# wsoc_con_dma_secure register map
Vendor: Texas Instruments
Peripheral module from a debugger description file (folder CC35X1).
Registers are 32-bit, access per field, reset 0x0 unless marked. A register's access mark holds for its fields unless they carry their own. Offsets are as the file gives them; lines under a group give offsets from that group; [hi:lo] are bit positions; {n}, {i} and the like mark numbered series; 'fields as' and 'values as' point back to an identical list; <NAME> marks a mode.

## wsoc_con_dma_secure
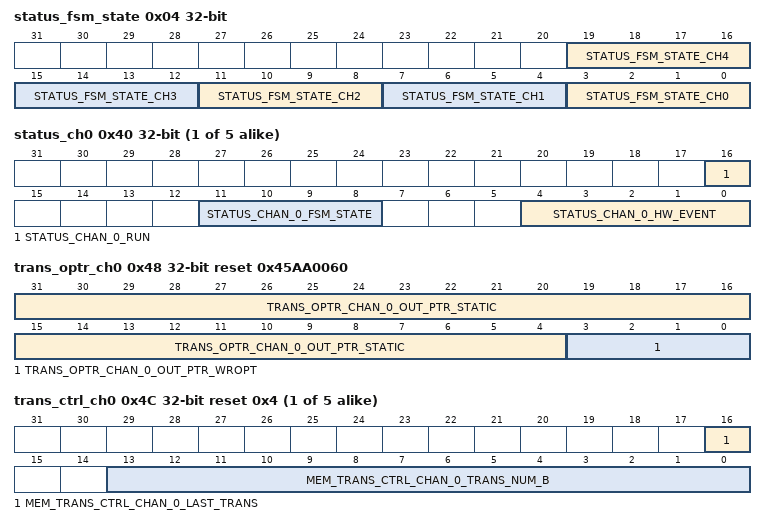
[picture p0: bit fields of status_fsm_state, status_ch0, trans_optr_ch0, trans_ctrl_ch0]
0x04 status_fsm_state ro — STATUS_FSM_STATE FSM States for all channels in one register: 0 - AES_IN 1 - AES_OUT 2 - UART_IN 3 - UART_OUT 4 - General Purpose
  [all] fields
    0=IDLE (Run command not recieved yet, Host is allowed to configure control registers, read status registers and execute a run command.); 1=PAUSE (Pause command recieved and irq raised. run command required to resume operation.); 2=EXCEPTION (Channel has encountered an error and requires assistance from host.); 3=DRAIN (ABORT or EXPECTION happend, draining FIFO.); 4=ABORT (SW abort signal, host must send Init command for channel to become active again.); 5=PRE_PAUSE (Copying remaining alignemnt buffer Bytes on write after pause command.); 7=LAST_2_PAUSE (Flushing write address aligner after pause command.); 8=PENDING_ARB (Channel is active, but arbiter has selected another channel for current transfer.); 9=COPY (Channel is active and is currently transferring data.); 10=COPY_LAST (Channel is active and is currently transfering the last block of data for current transaction.); 11=PAD (Channel is padding last block of Job.); 12=DONE (Transaction has completed, this state is active for one cycle. Next state is IDLE.); 13=SAVE_CTX (waiting for vbusp wready to transfer last word of block.); 14=WAIT_NXT_TRANS (Similar to IDLE, but explicitly states we are waiting for response from host.); 15=LAST_NO_PAD (The last transaction of last block of job when we do not do padding.)
  [4n+3:4n] STATUS_FSM_STATE_CH{n} (n=0..4) — Channel FSM State, see Enumeration for details
0x20 iidx ro — This register provides the highest priority enabled interrupt index. 0x00. means no event pending, 0x01 means interrupt pending for channel 0, 0x07 means interrupt pending for channel 6. Interrupt 1 is the highest priority, 2 next highest, 3,4, ...,7 is the least priority. That is, the least bit position that is set to 1 denotes the highest priority pending interrupt. channel 1 has highest priority, channel 6 has lowest. On each read, only one interrupt is indicated. On a read, the current interrupt (highest priority) is automatically cleared by the hardware and the corresponding interrupt flag in the RIS and MIS are cleared as well. After a read from the CPU (not from the debug interface), the register must be updated with the next highest priority interrupt, if none are pending, then it should display 0h
  [4:0] IIDX_STAT_RDCL — index of highest priority pending interrupt
    0=NO_INTR (No bit is set means there is no pending interrupt request); 1=IRQ_0 (Read and clear channel 0 irq); 2=IRQ_1 (Read and clear channel 1 irq); 4=IRQ_2 (Read and clear channel 2 irq); 3=IRQ_3 (Read and clear channel 3 irq); 5=IRQ_4 (Read and clear channel 4 irq); 6=IRQ_5 (Read and clear channel 5 irq); 7=IRQ_6 (Read and clear channel 6 irq)
0x24 imask — Interrupt mask. If a bit is set, then corresponding interrupt mask is set.
  [4:0] MEM_IMASK_IRQ rw — set 1 to enable irq
    0=DISABLED (Interrupt is masked out); 1=ENABLED (Interrupt will request an interrupt service routine and corresponding bit in [MIS] will be set)
0x28 ris ro — Raw interrupt status reflects all pending interrupts, regardless of masking. The RIS register allows the user to implement a poll scheme. A flag set in this register can be cleared by writing 1 to the ICLR register bit even if the corresponding IMASK bit is not enabled.
  [4:0] RIS_IRQ — bitmap of channel irqs
    1=SET (IRQ occured); 0=CLR (IRQ did not occur)
0x2C mis ro — Masked interrupt status. This is an AND of the IMASK and RIS registers.
  [4:0] MIS_IRQ — bitmap of channel irqs
    1=SET (IRQ occured); 0=CLR (IRQ did not occur)
0x30 iset — ISET allows interrupts to be set by software (useful in diagnostics and safety checks). Writing a 1 to a bit in ISET will set the event and therefore the related RIS bit also gets set. If the interrupt is enabled through the mask, then the corresponding MIS bit is also set.
  [4:0] ISET_IRQ_WRCL wo — set 1 to set channel
    0=NO_EFFECT (Writing 0 has no effect); 1=SET ([RIS] bit corresponding to IRQ_EXAMPLE0 is set)
0x34 iclr — Write a 1 to clear corresponding Interrupt.
  [4:0] ICLR_IRQ_WRCL wo — set 1 to clear irq
    0=NO_EFFECT (Writing 0 has no effect); 1=CLR ([RIS] clear bit corresponding to IRQ)
{0x40+0x20*i} status_ch{i} ro (i=0..4) — Channel Status FSM state and run indication.
  [16] STATUS_CHAN_{i}_RUN — Indication that channel is currently transfering data and is not idle. Channels that are waiting on arbitration are considered running.
    0=INACTIVE (Channel is IDLE or waiting for HOST); 1=ACTIVE (Channel is copying data or waiting on arbitration)
  [11:8] STATUS_CHAN_{i}_FSM_STATE — Channel FSM State, see Enumeration for details
    values as the fields of status_fsm_state
  [4:0] STATUS_CHAN_{i}_HW_EVENT — Channel status, bit mask. Multiple bits can be set at the same time
    0=NO_EVENT (No pending event); 1=JOB_DONE; 2=TRANS_DONE (Transaction done); 4=ABORTED (Transaction aborted by SW); 8=PAUSED (Transaction paused by SW); 16=EXC (An error has occured)
0x44 trans_iptr_ch0 rw — 32 bit address pointer of channel current input.
  [31:0] TRANS_IPTR_CHAN_0_IN_PTR_WROPT — address
0x48 trans_optr_ch0 reset 0x45AA0060 — 32 bit address pointer of channel current output.
  [31:4] TRANS_OPTR_CHAN_0_OUT_PTR_STATIC ro — address
  [3:0] TRANS_OPTR_CHAN_0_OUT_PTR_WROPT rw — address
{0x4C+0x20*i} trans_ctrl_ch{i} reset 0x4 (i=0..4) — Transaction control
  [16] MEM_TRANS_CTRL_CHAN_{i}_LAST_TRANS rw — Indicates this is the last DMA transaction on a specific crypto job, and therefore, the padding should apply to it. If this DMA transaction is not last, the channel must buffer the incomplete word and wait for the next DMA transaction command to be able to fetch the missing bytes. Once the last byte is reached, the DMA shall pad the remaining bytes. 0: not last transaction 1: last transaction
  [13:0] MEM_TRANS_CTRL_CHAN_{i}_TRANS_NUM_B rw — Number of bytes of the transaction to move from source to destination.
{0x50+0x20*i} trans_ctrl2_ch{i} (i=0..4) — DMA command interface
  [3:0] TRANS_CTRL2_CHAN_{i}_CMD_WRCL wo — command to resume, pause, stop or clear channel. STATUS_CHAN_X.RUN is a level signal that is high as long as the channel has not completed a tranfer.
    0=NOP (No effect); 1=RUN (Run - reactivate channel that is waiting on host. This is currently a pulse.); 2=PAUSE (Pause - stop reading data from source and change state to PAUSE once block has comleted.); 4=ABORT (Stop channel-operation immediately. Channel is in an invalid state until it is initialized again.); 8=INIT (Return Channel state to rest values. Requesred after an exception or Abort command were encountered to return channel to valid state.)
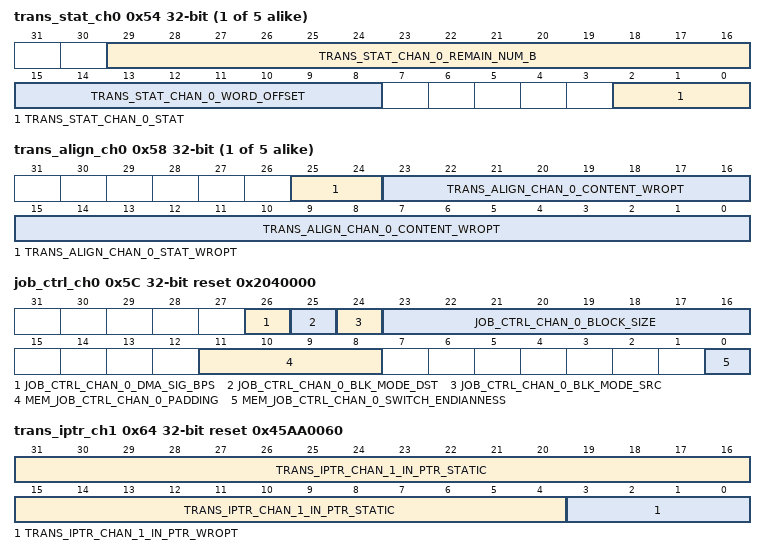
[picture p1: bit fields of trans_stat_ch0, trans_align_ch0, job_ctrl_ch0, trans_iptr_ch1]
{0x54+0x20*i} trans_stat_ch{i} ro (i=0..4) — Job completion reason - either last transaction or exception
  [29:16] TRANS_STAT_CHAN_{i}_REMAIN_NUM_B — Number of bytes remaining to complete the transaction. Loads (MEM_TRANS_NUM_B - TRANS_ALIGN.STAT_WROPT) and decrements the value for each transfer. This value should be read before context switch and written back to MEM_TRANS_NUM_B. The value of TRANS_ALIGN must be updated as well read and written back as well. The number of autstanding bytes should be equal to TRANS_STAT_CHAN_{i}_REMAIN_NUM_B+TRANS_ALIGN.CONTENT_WROPT
  [15:8] TRANS_STAT_CHAN_{i}_WORD_OFFSET — Offset in words from block boundary. Represents the number of words to be read from accelerator before context switch.
  [2:0] TRANS_STAT_CHAN_{i}_STAT — channel vbusp rstatus recieved at one of the master ports. Once an error is encountered the channel will enter an Exception state and stay the until an init command is recieved. ICLR does not affect this status.
    0=NO_ERR (No vbusp read error); 1=ADDR_ERR (Address error 1. No slave has this address 2. reserved address 3. wrong access type(read/write)); 2=PROTECTION_ERR (Improper priv/privid); 3=TIMEOUT_ERR (watchdog timeout - unsupported); 4=DATA_ERR (Data integrity error unsupported); 5=ADDR_MODE_ERR (vbus amode not supported); 7=EXCLUSIVE_RD_ERR (Exclusive read is not supported.); 6=MPPC_ERR (MPPC Fault occured)
{0x58+0x20*i} trans_align_ch{i} (i=0..4) — content and number of bytes in alignment buffer
  [25:24] TRANS_ALIGN_CHAN_{i}_STAT_WROPT rw — Number of bytes in the alignment buffer. In case of context switch, this field need to be read before context is swapped out and re written after the context is swapped back in.
    0=LEN_0 (No words in buffer); 1=LEN_1 (One word in buffer); 2=LEN_2 (Two words in buffer); 3=LEN_3 (Three words in buffer)
  [23:0] TRANS_ALIGN_CHAN_{i}_CONTENT_WROPT rw — 3 bytes of channel alignment FIFO. offset: 0x0: oldest data- lowest address 0x1: Data 0x2: Newest Data - highest address 0x3: Reserved
0x5C job_ctrl_ch0 reset 0x2040000 — Job control register
  [26] JOB_CTRL_CHAN_0_DMA_SIG_BPS ro — tie high channel DMA req signal. This is useful to change a channel dedicated to a specific crypto engine to a general usage channel.
    0=CLR (No channel is bypassed); 1=SET (channel bypass)
  [25] JOB_CTRL_CHAN_0_BLK_MODE_DST ro — Destination pointer wrap around mode 0: no wrap around(non block mode) 1: with wrap around(block mode)
  [24] JOB_CTRL_CHAN_0_BLK_MODE_SRC ro — source pointer wrap around mode 0: no wrap around(non block mode) 1: with wrap around(block mode)
  [23:16] JOB_CTRL_CHAN_0_BLOCK_SIZE ro — size of the block in words. If block mode is enabled, defines the address wrap around. Since channel arbitration decisions are made every block, this also effect how much bandwidth is given to a specific channel. AES - 4 UART - 1
  [11:8] MEM_JOB_CTRL_CHAN_0_PADDING rw — destination padding pattern. This field has only an effect if block_mode_dest is asserted. If the number of bytes provided is not sufficient to complete 1 block, the DMA engine shall pad the remaining bytes to provide 1 full block of data to the accelerator. Some of the accelerators already support a subset of padding schemes, hence a partial last block is not necessarily an error. Note that FIPS andf RFC are in big endian. See crypto engine documentation for details. 0: No Padding. If the DMA is unable to transfer a full word (and also finish a block), it must keep up to 3 bytes that were already read in a buffer. Once the next pointer (gather function) is programed (automatically or by the software), it resumes filling up words to complete a block. The buffer is cleared (might be a simple pointer re-init) by setting the init field to 1. 1: (Poly1305, AES-CCM) all zeros. 2: (AES-CMAC) 0x80 followed by all zeros. 3: (SHAKE) pad10*1. Depending on the rate (r=1600-c), the DMA forms an integer multiple of r. Message || 0x1F || 00...0 || 0x80. The DMA adds a 0x1F (for SHAKE) after the last byte of the message, then all 0s, then 0x80 at the last byte. 4: Pad with 0x01, 0x02, 0x03,...,0xn (where n is the number of padding bytes) (TBD as this one might very complex to implement along with the byte realignment requirement) 5: All zeros except for the last byte which says how many bytes of padding there are (ANSI X.923). E.g. 0x00 0x00 0x00 0x04 6: Pad with repeated byte stating how many padding bytes there are (PKCS#7 https://tools.ietf.org/html/rfc5652#section-6.3). E.g. 0x03 0x03 0x03 7: Pad with padding length. TLS padding: https://www.ietf.org/rfc/rfc5246.txt. Message + mac + padding length + padding length repeated. E.g. xx 0x03 0x03 0x03 0x03. (see section 6.2.3.2. of the link above for a full explanation). Note: SHA-1, 224, 256 & MD5 https://www.ietf.org/rfc/rfc1321.txt (3.1) http://nvlpubs.nist.gov/nistpubs/FIPS/NIST.FIPS.180-4.pdf (5.1.1) -Append 1 bit, then zero out to the 448th/512th bits. (The length of the message goes in 449-512). SHA-384, 512 http://nvlpubs.nist.gov/nistpubs/FIPS/NIST.FIPS.180-4.pdf (5.1.2) -Append 1 bit, zero out to the 896th/1024th bit.
    0=NO_PADDING (No Padding. If the DMA is unable to transfer a full word (and also finish a block), it must keep up to 3 bytes that were already read in a buffer. Once the next pointer (gather function) is programed (automatically or by the software), it resumes filling up words to complete a block. The buffer is cleared (might be a simple pointer re-init) by setting the init field to 1.); 1=ALL_ZEROS ((Poly1305, AES-CCM) all zeros.); 3=SHAKE ((SHAKE) pad10*1. Depending on the rate (r=1600-c), the DMA forms an integer multiple of r. Message || 0x1F || 00...0 || 0x80. The DMA adds a 0x1F (for SHAKE) after the last byte of the message, then all 0s, then 0x80 at the last byte.); 4=INCREMENT (Pad with 0x01, 0x02, 0x03,...,0xn (where n is the number of padding bytes) (TBD as this one might very complex to implement along with the byte realignment requirement)); 5=ANSIX923 (All zeros except for the last byte which says how many bytes of padding there are (ANSI X.923). E.g. 0x00 0x00 0x00 0x04); 6=PKCS7 (Pad with repeated byte stating how many padding bytes there are (PKCS#7 https://tools.ietf.org/html/rfc5652#section-6.3). E.g. 0x03 0x03 0x03); 7=TLS (Pad with padding length. TLS padding: https://www.ietf.org/rfc/rfc5246.txt. Message + mac + padding length + padding length repeated. E.g. xx 0x03 0x03 0x03 0x03. (see section 6.2.3.2. of the link above for a full explanation).)
  [0] MEM_JOB_CTRL_CHAN_0_SWITCH_ENDIANNESS rw — source pointer wrap around mode 0: no wrap around(non block mode) 1: with wrap around(block mode)
    0=NO_ENDIANNESS_SWITCH; 1=SWITCH_ENDIANNESS
0x64 trans_iptr_ch1 reset 0x45AA0060 — 32 bit address pointer of channel current input.
  [31:4] TRANS_IPTR_CHAN_1_IN_PTR_STATIC ro — address
  [3:0] TRANS_IPTR_CHAN_1_IN_PTR_WROPT rw — address
0x68 trans_optr_ch1 rw — 32 bit address pointer of channel current output.
  [31:0] TRANS_OPTR_CHAN_1_OUT_PTR_WROPT — address
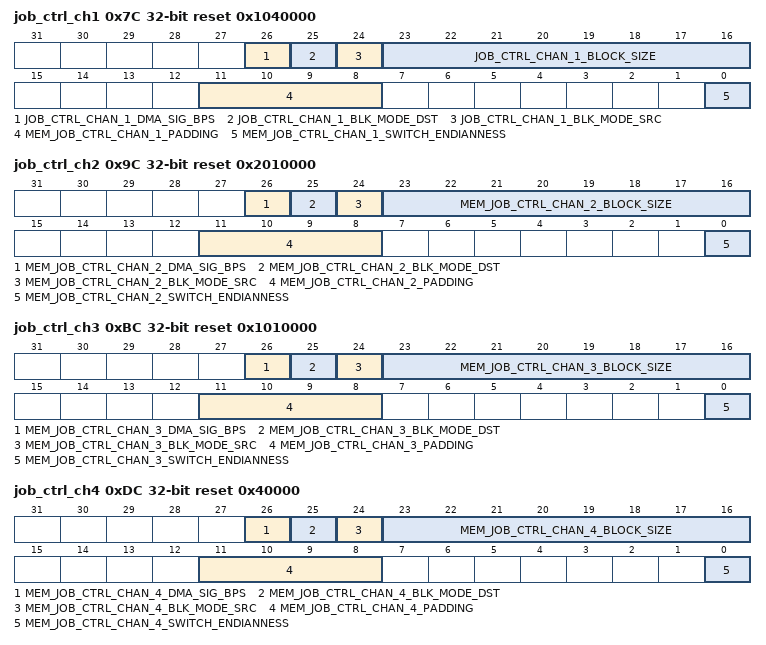
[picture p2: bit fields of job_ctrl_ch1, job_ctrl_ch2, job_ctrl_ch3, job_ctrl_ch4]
0x7C job_ctrl_ch1 reset 0x1040000 — Job control register
  [26] JOB_CTRL_CHAN_1_DMA_SIG_BPS ro — tie high channel DMA req signal. This is useful to change a channel dedicated to a specific crypto engine to a general usage channel.
    0=CLR (No channel is bypassed); 1=SET (channel bypass)
  [25] JOB_CTRL_CHAN_1_BLK_MODE_DST ro — Destination pointer wrap around mode 0: no wrap around(non block mode) 1: with wrap around(block mode)
  [24] JOB_CTRL_CHAN_1_BLK_MODE_SRC ro — source pointer wrap around mode 0: no wrap around(non block mode) 1: with wrap around(block mode)
  [23:16] JOB_CTRL_CHAN_1_BLOCK_SIZE ro — size of the block in words. If block mode is enabled, defines the address wrap around. Since channel arbitration decisions are made every block, this also effect how much bandwidth is given to a specific channel. AES - 4 UART - 1
  [11:8] MEM_JOB_CTRL_CHAN_1_PADDING rw — destination padding pattern. This field has only an effect if block_mode_dest is asserted. If the number of bytes provided is not sufficient to complete 1 block, the DMA engine shall pad the remaining bytes to provide 1 full block of data to the accelerator. Some of the accelerators already support a subset of padding schemes, hence a partial last block is not necessarily an error. Note that FIPS andf RFC are in big endian. See crypto engine documentation for details. 0: No Padding. If the DMA is unable to transfer a full word (and also finish a block), it must keep up to 3 bytes that were already read in a buffer. Once the next pointer (gather function) is programed (automatically or by the software), it resumes filling up words to complete a block. The buffer is cleared (might be a simple pointer re-init) by setting the init field to 1. 1: (Poly1305, AES-CCM) all zeros. 2: (AES-CMAC) 0x80 followed by all zeros. 3: (SHAKE) pad10*1. Depending on the rate (r=1600-c), the DMA forms an integer multiple of r. Message || 0x1F || 00...0 || 0x80. The DMA adds a 0x1F (for SHAKE) after the last byte of the message, then all 0s, then 0x80 at the last byte. 4: Pad with 0x01, 0x02, 0x03,...,0xn (where n is the number of padding bytes) (TBD as this one might very complex to implement along with the byte realignment requirement) 5: All zeros except for the last byte which says how many bytes of padding there are (ANSI X.923). E.g. 0x00 0x00 0x00 0x04 6: Pad with repeated byte stating how many padding bytes there are (PKCS#7 https://tools.ietf.org/html/rfc5652#section-6.3). E.g. 0x03 0x03 0x03 7: Pad with padding length. TLS padding: https://www.ietf.org/rfc/rfc5246.txt. Message + mac + padding length + padding length repeated. E.g. xx 0x03 0x03 0x03 0x03. (see section 6.2.3.2. of the link above for a full explanation). Note: SHA-1, 224, 256 & MD5 https://www.ietf.org/rfc/rfc1321.txt (3.1) http://nvlpubs.nist.gov/nistpubs/FIPS/NIST.FIPS.180-4.pdf (5.1.1) -Append 1 bit, then zero out to the 448th/512th bits. (The length of the message goes in 449-512). SHA-384, 512 http://nvlpubs.nist.gov/nistpubs/FIPS/NIST.FIPS.180-4.pdf (5.1.2) -Append 1 bit, zero out to the 896th/1024th bit.
    values as job_ctrl_ch0.MEM_JOB_CTRL_CHAN_0_PADDING
  [0] MEM_JOB_CTRL_CHAN_1_SWITCH_ENDIANNESS rw — source pointer wrap around mode 0: no wrap around(non block mode) 1: with wrap around(block mode)
    0=NO_ENDIANNESS_SWITCH; 1=SWITCH_ENDIANNESS
0x84 trans_iptr_ch2 rw — 32 bit address pointer of channel current input.
  [31:0] TRANS_IPTR_CHAN_2_IN_PTR_WROPT — address
0x88 trans_optr_ch2 rw reset 0x45860000 — 32 bit address pointer of channel current output.
  [31:0] TRANS_OPTR_CHAN_2_OUT_PTR_WROPT — address
0x9C job_ctrl_ch2 reset 0x2010000 — Job control register
  [26] MEM_JOB_CTRL_CHAN_2_DMA_SIG_BPS rw — tie high channel DMA req signal. This is useful to change a channel dedicated to a specific crypto engine to a general usage channel.
    0=CLR (No channel is bypassed); 1=SET (channel bypass)
  [25] MEM_JOB_CTRL_CHAN_2_BLK_MODE_DST rw — Destination pointer wrap around mode 0: no wrap around(non block mode) 1: with wrap around(block mode)
  [24] MEM_JOB_CTRL_CHAN_2_BLK_MODE_SRC rw — source pointer wrap around mode 0: no wrap around(non block mode) 1: with wrap around(block mode)
  [23:16] MEM_JOB_CTRL_CHAN_2_BLOCK_SIZE rw — size of the block in words. If block mode is enabled, defines the address wrap around. Since channel arbitration decisions are made every block, this also effect how much bandwidth is given to a specific channel. AES - 4 UART - 1
  [11:8] MEM_JOB_CTRL_CHAN_2_PADDING rw — destination padding pattern. This field has only an effect if block_mode_dest is asserted. If the number of bytes provided is not sufficient to complete 1 block, the DMA engine shall pad the remaining bytes to provide 1 full block of data to the accelerator. Some of the accelerators already support a subset of padding schemes, hence a partial last block is not necessarily an error. Note that FIPS andf RFC are in big endian. See crypto engine documentation for details. 0: No Padding. If the DMA is unable to transfer a full word (and also finish a block), it must keep up to 3 bytes that were already read in a buffer. Once the next pointer (gather function) is programed (automatically or by the software), it resumes filling up words to complete a block. The buffer is cleared (might be a simple pointer re-init) by setting the init field to 1. 1: (Poly1305, AES-CCM) all zeros. 2: (AES-CMAC) 0x80 followed by all zeros. 3: (SHAKE) pad10*1. Depending on the rate (r=1600-c), the DMA forms an integer multiple of r. Message || 0x1F || 00...0 || 0x80. The DMA adds a 0x1F (for SHAKE) after the last byte of the message, then all 0s, then 0x80 at the last byte. 4: Pad with 0x01, 0x02, 0x03,...,0xn (where n is the number of padding bytes) (TBD as this one might very complex to implement along with the byte realignment requirement) 5: All zeros except for the last byte which says how many bytes of padding there are (ANSI X.923). E.g. 0x00 0x00 0x00 0x04 6: Pad with repeated byte stating how many padding bytes there are (PKCS#7 https://tools.ietf.org/html/rfc5652#section-6.3). E.g. 0x03 0x03 0x03 7: Pad with padding length. TLS padding: https://www.ietf.org/rfc/rfc5246.txt. Message + mac + padding length + padding length repeated. E.g. xx 0x03 0x03 0x03 0x03. (see section 6.2.3.2. of the link above for a full explanation). Note: SHA-1, 224, 256 & MD5 https://www.ietf.org/rfc/rfc1321.txt (3.1) http://nvlpubs.nist.gov/nistpubs/FIPS/NIST.FIPS.180-4.pdf (5.1.1) -Append 1 bit, then zero out to the 448th/512th bits. (The length of the message goes in 449-512). SHA-384, 512 http://nvlpubs.nist.gov/nistpubs/FIPS/NIST.FIPS.180-4.pdf (5.1.2) -Append 1 bit, zero out to the 896th/1024th bit.
    values as job_ctrl_ch0.MEM_JOB_CTRL_CHAN_0_PADDING
  [0] MEM_JOB_CTRL_CHAN_2_SWITCH_ENDIANNESS rw — source pointer wrap around mode 0: no wrap around(non block mode) 1: with wrap around(block mode)
    0=NO_ENDIANNESS_SWITCH; 1=SWITCH_ENDIANNESS
0xA4 trans_iptr_ch3 rw reset 0x45860000 — 32 bit address pointer of channel current input.
  [31:0] TRANS_IPTR_CHAN_3_IN_PTR_WROPT — address
0xA8 trans_optr_ch3 rw — 32 bit address pointer of channel current output.
  [31:0] TRANS_OPTR_CHAN_3_OUT_PTR_WROPT — address
0xBC job_ctrl_ch3 reset 0x1010000 — Job control register
  [26] MEM_JOB_CTRL_CHAN_3_DMA_SIG_BPS rw — tie high channel DMA req signal. This is useful to change a channel dedicated to a specific crypto engine to a general usage channel.
    0=CLR (No channel is bypassed); 1=SET (channel bypass)
  [25] MEM_JOB_CTRL_CHAN_3_BLK_MODE_DST rw — Destination pointer wrap around mode 0: no wrap around(non block mode) 1: with wrap around(block mode)
  [24] MEM_JOB_CTRL_CHAN_3_BLK_MODE_SRC rw — source pointer wrap around mode 0: no wrap around(non block mode) 1: with wrap around(block mode)
  [23:16] MEM_JOB_CTRL_CHAN_3_BLOCK_SIZE rw — size of the block in words. If block mode is enabled, defines the address wrap around. Since channel arbitration decisions are made every block, this also effect how much bandwidth is given to a specific channel. AES - 4 UART - 1
  [11:8] MEM_JOB_CTRL_CHAN_3_PADDING rw — destination padding pattern. This field has only an effect if block_mode_dest is asserted. If the number of bytes provided is not sufficient to complete 1 block, the DMA engine shall pad the remaining bytes to provide 1 full block of data to the accelerator. Some of the accelerators already support a subset of padding schemes, hence a partial last block is not necessarily an error. Note that FIPS andf RFC are in big endian. See crypto engine documentation for details. 0: No Padding. If the DMA is unable to transfer a full word (and also finish a block), it must keep up to 3 bytes that were already read in a buffer. Once the next pointer (gather function) is programed (automatically or by the software), it resumes filling up words to complete a block. The buffer is cleared (might be a simple pointer re-init) by setting the init field to 1. 1: (Poly1305, AES-CCM) all zeros. 2: (AES-CMAC) 0x80 followed by all zeros. 3: (SHAKE) pad10*1. Depending on the rate (r=1600-c), the DMA forms an integer multiple of r. Message || 0x1F || 00...0 || 0x80. The DMA adds a 0x1F (for SHAKE) after the last byte of the message, then all 0s, then 0x80 at the last byte. 4: Pad with 0x01, 0x02, 0x03,...,0xn (where n is the number of padding bytes) (TBD as this one might very complex to implement along with the byte realignment requirement) 5: All zeros except for the last byte which says how many bytes of padding there are (ANSI X.923). E.g. 0x00 0x00 0x00 0x04 6: Pad with repeated byte stating how many padding bytes there are (PKCS#7 https://tools.ietf.org/html/rfc5652#section-6.3). E.g. 0x03 0x03 0x03 7: Pad with padding length. TLS padding: https://www.ietf.org/rfc/rfc5246.txt. Message + mac + padding length + padding length repeated. E.g. xx 0x03 0x03 0x03 0x03. (see section 6.2.3.2. of the link above for a full explanation). Note: SHA-1, 224, 256 & MD5 https://www.ietf.org/rfc/rfc1321.txt (3.1) http://nvlpubs.nist.gov/nistpubs/FIPS/NIST.FIPS.180-4.pdf (5.1.1) -Append 1 bit, then zero out to the 448th/512th bits. (The length of the message goes in 449-512). SHA-384, 512 http://nvlpubs.nist.gov/nistpubs/FIPS/NIST.FIPS.180-4.pdf (5.1.2) -Append 1 bit, zero out to the 896th/1024th bit.
    values as job_ctrl_ch0.MEM_JOB_CTRL_CHAN_0_PADDING
  [0] MEM_JOB_CTRL_CHAN_3_SWITCH_ENDIANNESS rw — source pointer wrap around mode 0: no wrap around(non block mode) 1: with wrap around(block mode)
    0=NO_ENDIANNESS_SWITCH; 1=SWITCH_ENDIANNESS
0xC4 trans_iptr_ch4 rw — 32 bit address pointer of channel current input.
  [31:0] TRANS_IPTR_CHAN_4_IN_PTR_WROPT — address
0xC8 trans_optr_ch4 rw — 32 bit address pointer of channel current output.
  [31:0] TRANS_OPTR_CHAN_4_OUT_PTR_WROPT — address
0xDC job_ctrl_ch4 reset 0x40000 — Job control register
  [26] MEM_JOB_CTRL_CHAN_4_DMA_SIG_BPS rw — tie high channel DMA req signal. This is useful to change a channel dedicated to a specific crypto engine to a general usage channel.
    0=CLR (No channel is bypassed); 1=SET (channel bypass)
  [25] MEM_JOB_CTRL_CHAN_4_BLK_MODE_DST rw — Destination pointer wrap around mode 0: no wrap around(non block mode) 1: with wrap around(block mode)
  [24] MEM_JOB_CTRL_CHAN_4_BLK_MODE_SRC rw — source pointer wrap around mode 0: no wrap around(non block mode) 1: with wrap around(block mode)
  [23:16] MEM_JOB_CTRL_CHAN_4_BLOCK_SIZE rw — size of the block in words. If block mode is enabled, defines the address wrap around. Since channel arbitration decisions are made every block, this also effect how much bandwidth is given to a specific channel. AES - 4 UART - 1
  [11:8] MEM_JOB_CTRL_CHAN_4_PADDING rw — destination padding pattern. This field has only an effect if block_mode_dest is asserted. If the number of bytes provided is not sufficient to complete 1 block, the DMA engine shall pad the remaining bytes to provide 1 full block of data to the accelerator. Some of the accelerators already support a subset of padding schemes, hence a partial last block is not necessarily an error. Note that FIPS andf RFC are in big endian. See crypto engine documentation for details. 0: No Padding. If the DMA is unable to transfer a full word (and also finish a block), it must keep up to 3 bytes that were already read in a buffer. Once the next pointer (gather function) is programed (automatically or by the software), it resumes filling up words to complete a block. The buffer is cleared (might be a simple pointer re-init) by setting the init field to 1. 1: (Poly1305, AES-CCM) all zeros. 2: (AES-CMAC) 0x80 followed by all zeros. 3: (SHAKE) pad10*1. Depending on the rate (r=1600-c), the DMA forms an integer multiple of r. Message || 0x1F || 00...0 || 0x80. The DMA adds a 0x1F (for SHAKE) after the last byte of the message, then all 0s, then 0x80 at the last byte. 4: Pad with 0x01, 0x02, 0x03,...,0xn (where n is the number of padding bytes) (TBD as this one might very complex to implement along with the byte realignment requirement) 5: All zeros except for the last byte which says how many bytes of padding there are (ANSI X.923). E.g. 0x00 0x00 0x00 0x04 6: Pad with repeated byte stating how many padding bytes there are (PKCS#7 https://tools.ietf.org/html/rfc5652#section-6.3). E.g. 0x03 0x03 0x03 7: Pad with padding length. TLS padding: https://www.ietf.org/rfc/rfc5246.txt. Message + mac + padding length + padding length repeated. E.g. xx 0x03 0x03 0x03 0x03. (see section 6.2.3.2. of the link above for a full explanation). Note: SHA-1, 224, 256 & MD5 https://www.ietf.org/rfc/rfc1321.txt (3.1) http://nvlpubs.nist.gov/nistpubs/FIPS/NIST.FIPS.180-4.pdf (5.1.1) -Append 1 bit, then zero out to the 448th/512th bits. (The length of the message goes in 449-512). SHA-384, 512 http://nvlpubs.nist.gov/nistpubs/FIPS/NIST.FIPS.180-4.pdf (5.1.2) -Append 1 bit, zero out to the 896th/1024th bit.
    values as job_ctrl_ch0.MEM_JOB_CTRL_CHAN_0_PADDING
  [0] MEM_JOB_CTRL_CHAN_4_SWITCH_ENDIANNESS rw — source pointer wrap around mode 0: no wrap around(non block mode) 1: with wrap around(block mode)
    0=NO_ENDIANNESS_SWITCH; 1=SWITCH_ENDIANNESS
